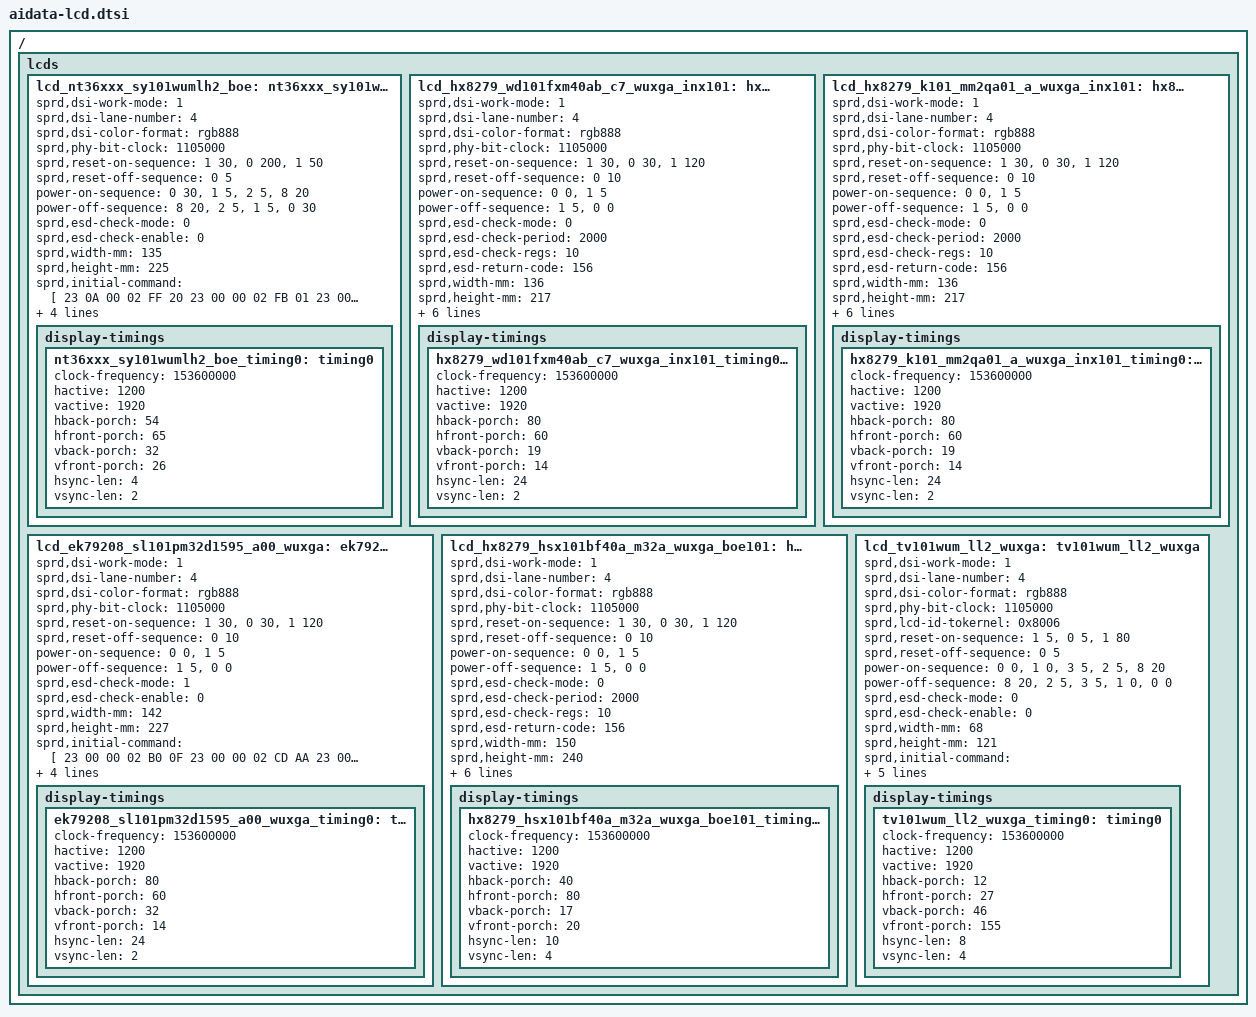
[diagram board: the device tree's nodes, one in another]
// SPDX-License-Identifier: GPL-2.0
/*
 * Aidata Adt1061 LCD Panel
 */

/ { lcds {
	lcd_nt36xxx_sy101wumlh2_boe: nt36xxx_sy101wumlh2_boe {
		sprd,dsi-work-mode = <1>; /* video burst mode */
		sprd,dsi-lane-number = <4>;
		sprd,dsi-color-format = "rgb888";

		sprd,phy-bit-clock = <1105000>;	/* kbps */

		sprd,reset-on-sequence = <1 30>, <0 200>, <1 50>;
		sprd,reset-off-sequence = <0 5>;

		power-on-sequence = <0 30>, <1 5>, <2 5>, <8 20>;
		power-off-sequence = <8 20>, <2 5>, <1 5>, <0 30>;

		sprd,esd-check-mode = <0>;
		sprd,esd-check-enable = <0>;

		sprd,width-mm = <135>;
		sprd,height-mm = <225>;

		sprd,initial-command = [
			23  0A  00  02  FF  20
			23  00  00  02  FB  01
			23  00  00  02  05  D1
			23  00  00  02  07  8C
			23  00  00  02  08  46
			23  00  00  02  0D  63
			23  00  00  02  0E  AC
			23  00  00  02  0F  5F
			23  00  00  02  89  79
			23  00  00  02  8A  79
			23  00  00  02  8B  79
			23  00  00  02  8C  79
			23  00  00  02  95  FF
			23  00  00  02  96  FF
			23  00  00  02  30  11
			23  00  00  02  58  60
			23  00  00  02  6D  66
			23  00  00  02  75  A2
			23  00  00  02  77  B3
			39  00  00  11  B0  00  B6  00  BF  00  D3  00  E4  00  F2  01  01  01  0D  01  1A
			39  00  00  11  B1  01  27  01  4F  01  71  01  A6  01  D3  02  19  02  52  02  54
			39  00  00  11  B2  02  8D  02  CF  02  F7  03  2C  03  4D  03  79  03  86  03  95
			39  00  00  0D  B3  03  A4  03  B4  03  D5  03  ED  03  FE  03  FF
			39  00  00  11  B4  00  16  00  30  00  57  00  77  00  93  00  AB  00  C1  00  D4
			39  00  00  11  B5  00  E5  01  1F  01  4B  01  8E  01  C0  02  0D  02  4B  02  4D
			39  00  00  11  B6  02  88  02  CB  02  F2  03  27  03  4A  03  74  03  83  03  91
			39  00  00  0D  B7  03  A1  03  B2  03  D2  03  EC  03  FE  03  FF
			39  00  00  11  B8  00  08  00  2C  00  57  00  7A  00  99  00  B1  00  C7  00  DC
			39  00  00  11  B9  00  EE  01  28  01  54  01  96  01  C7  02  13  02  4F  02  51
			39  00  00  11  BA  02  8B  02  CD  02  F4  03  2A  03  4D  03  78  03  86  03  94
			39  00  00  0D  BB  03  A4  03  B4  03  D5  03  EC  03  FE  03  FF
			23  00  00  02  FF  21
			23  00  00  02  FB  01
			39  00  00  11  B0  00  AE  00  B7  00  CB  00  DC  00  EA  00  F9  01  05  01  12
			39  00  00  11  B1  01  1F  01  47  01  69  01  9E  01  CB  02  11  02  4A  02  4C
			39  00  00  11  B2  02  85  02  C7  02  EF  03  24  03  45  03  71  03  7E  03  8D
			39  00  00  0D  B3  03  9C  03  AC  03  CD  03  E5  03  F6  03  F7
			39  00  00  11  B4  00  0E  00  28  00  4F  00  6F  00  8B  00  A3  00  B9  00  CC
			39  00  00  11  B5  00  DD  01  17  01  43  01  86  01  B8  02  05  02  43  02  45
			39  00  00  11  B6  02  80  02  C3  02  EA  03  1F  03  42  03  6C  03  7B  03  89
			39  00  00  0D  B7  03  99  03  AA  03  CA  03  E4  03  F6  03  F7
			39  00  00  11  B8  00  00  00  24  00  4F  00  72  00  91  00  A9  00  BF  00  D4
			39  00  00  11  B9  00  E6  01  20  01  4C  01  8E  01  BF  02  0B  02  47  02  49
			39  00  00  11  BA  02  83  02  C5  02  EC  03  22  03  45  03  70  03  7E  03  8C
			39  00  00  0D  BB  03  9C  03  AC  03  CD  03  E4  03  F6  03  F7
			23  00  00  02  FF  24
			23  00  00  02  FB  01
			23  00  00  02  00  00
			23  00  00  02  01  00
			23  00  00  02  02  22
			23  00  00  02  03  08
			23  00  00  02  04  04
			23  00  00  02  05  23
			23  00  00  02  06  21
			23  00  00  02  07  20
			23  00  00  02  08  0F
			23  00  00  02  09  0F
			23  00  00  02  0A  0E
			23  00  00  02  0B  0E
			23  00  00  02  0C  0D
			23  00  00  02  0D  0D
			23  00  00  02  0E  0C
			23  00  00  02  0F  0C
			23  00  00  02  10  00
			23  00  00  02  11  00
			23  00  00  02  12  00
			23  00  00  02  13  00
			23  00  00  02  14  00
			23  00  00  02  15  00
			23  00  00  02  16  00
			23  00  00  02  17  00
			23  00  00  02  18  22
			23  00  00  02  19  08
			23  00  00  02  1A  04
			23  00  00  02  1B  23
			23  00  00  02  1C  21
			23  00  00  02  1D  20
			23  00  00  02  1E  0F
			23  00  00  02  1F  0F
			23  00  00  02  20  0E
			23  00  00  02  21  0E
			23  00  00  02  22  0D
			23  00  00  02  23  0D
			23  00  00  02  24  0C
			23  00  00  02  25  0C
			23  00  00  02  26  00
			23  00  00  02  27  00
			23  00  00  02  28  00
			23  00  00  02  29  00
			23  00  00  02  2A  00
			23  00  00  02  2B  00
			23  00  00  02  2F  54
			23  00  00  02  33  54
			23  00  00  02  3A  9A
			23  00  00  02  3B  A0
			23  00  00  02  3D  91
			23  00  00  02  3F  08
			23  00  00  02  43  08
			23  00  00  02  4A  9A
			23  00  00  02  4B  A0
			23  00  00  02  4C  91
			23  00  00  02  4D  43
			23  00  00  02  4E  21
			23  00  00  02  51  12
			23  00  00  02  52  34
			39  00  00  03  55  86  07
			23  00  00  02  56  04
			23  00  00  02  58  21
			23  00  00  02  59  30
			23  00  00  02  5A  BA
			23  00  00  02  5B  96
			39  00  00  03  5E  00  12
			23  00  00  02  5F  00
			23  00  00  02  65  82
			23  00  00  02  AD  00
			23  00  00  02  AE  01
			23  00  00  02  AF  0C
			23  00  00  02  B0  16
			23  00  00  02  B1  0B
			23  00  00  02  B2  15
			23  00  00  02  B3  00
			23  00  00  02  C4  20
			39  00  00  0D  B6  05  00  05  00  00  00  00  00  05  05  00  00
			23  00  00  02  60  96
			23  00  00  02  61  80
			23  00  00  02  63  70
			23  00  00  02  92  DF
			23  00  00  02  93  1A
			23  00  00  02  94  0A
			23  00  00  02  D7  55
			23  00  00  02  DA  0A
			23  00  00  02  DE  08
			23  00  00  02  DB  05
			23  00  00  02  DC  DF
			23  00  00  02  DD  22
			23  00  00  02  DF  05
			23  00  00  02  E0  DF
			23  00  00  02  E1  05
			23  00  00  02  E2  DF
			23  00  00  02  E3  05
			23  00  00  02  E4  DF
			23  00  00  02  E5  05
			23  00  00  02  E6  DF
			23  00  00  02  5C  88
			23  00  00  02  5D  08
			23  00  00  02  8D  88
			23  00  00  02  8E  08
			23  00  00  02  B5  90
			23  00  00  02  FF  25
			23  00  00  02  FB  01
			23  00  00  02  05  04
			23  00  00  02  19  07
			23  00  00  02  1F  BA
			23  00  00  02  20  96
			23  00  00  02  26  BA
			23  00  00  02  27  96
			23  00  00  02  33  BA
			23  00  00  02  34  96
			23  00  00  02  3F  E0
			23  00  00  02  40  00
			23  00  00  02  44  00
			23  00  00  02  45  40
			23  00  00  02  48  BA
			23  00  00  02  49  96
			23  00  00  02  5B  00
			23  00  00  02  5C  00
			23  00  00  02  5D  00
			23  00  00  02  5E  D0
			23  00  00  02  61  BA
			23  00  00  02  62  96
			23  00  00  02  F1  10
			23  00  00  02  FF  2A
			23  00  00  02  FB  01
			23  00  00  02  64  16
			23  00  00  02  67  16
			23  00  00  02  6A  16
			23  00  00  02  73  9E
			23  00  00  02  76  16
			23  00  00  02  79  9E
			23  00  00  02  7C  16
			23  00  00  02  A2  F3
			23  00  00  02  A3  FF
			23  00  00  02  A4  FF
			23  00  00  02  A5  FF
			23  00  00  02  D6  08
			23  00  00  02  FF  26
			23  00  00  02  FB  01
			23  00  00  02  00  A1
			23  00  00  02  0A  F2
			23  00  00  02  04  28
			23  00  00  02  06  2A
			23  00  00  02  0C  11
			23  00  00  02  0D  00
			23  00  00  02  0F  09
			23  00  00  02  11  10
			23  00  00  02  12  50
			23  00  00  02  13  6A
			23  00  00  02  14  76
			23  00  00  02  15  00
			23  00  00  02  16  90
			23  00  00  02  17  A0
			23  00  00  02  18  86
			23  00  00  02  19  0F
			23  00  00  02  1A  9C
			23  00  00  02  1B  0E
			23  00  00  02  1C  DC
			23  00  00  02  22  00
			23  00  00  02  23  00
			23  00  00  02  2A  0F
			23  00  00  02  2B  9C
			23  00  00  02  1D  00
			23  00  00  02  1E  DF
			23  00  00  02  1F  DF
			23  00  00  02  24  00
			23  00  00  02  25  DF
			23  00  00  02  2F  05
			23  00  00  02  30  DF
			23  00  00  02  31  00
			23  00  00  02  32  DF
			23  00  00  02  39  00
			23  00  00  02  3A  DF
			23  00  00  02  20  01
			23  00  00  02  33  11
			23  00  00  02  34  78
			23  00  00  02  35  16
			23  00  00  02  C8  00
			23  00  00  02  C9  00
			23  00  00  02  CA  4E
			23  00  00  02  CB  00
			23  00  00  02  A9  6D
			23  00  00  02  AA  71
			23  00  00  02  AB  73
			23  00  00  02  AC  76
			23  00  00  02  FF  27
			23  00  00  02  FB  01
			23  00  00  02  58  00
			23  00  00  02  00  00
			23  00  00  02  78  00
			23  00  00  02  C3  00
			23  00  00  02  D1  24
			23  00  00  02  D2  30
			23  00  00  02  FF  23
			23  00  00  02  FB  01
			23  00  00  02  00  80
			23  00  00  02  05  2A
			23  00  00  02  07  00
			23  00  00  02  11  01
			23  00  00  02  12  68
			23  00  00  02  15  E9
			23  00  00  02  16  0C
			23  00  00  02  2B  10
			23  00  00  02  58  FF
			23  00  00  02  59  FF
			23  00  00  02  5A  FE
			23  00  00  02  5B  FD
			23  00  00  02  5C  FD
			23  00  00  02  5D  FC
			23  00  00  02  5E  FB
			23  00  00  02  5F  F9
			23  00  00  02  60  F7
			23  00  00  02  61  F3
			23  00  00  02  62  EA
			23  00  00  02  63  E6
			23  00  00  02  64  E0
			23  00  00  02  65  DD
			23  00  00  02  66  DB
			23  00  00  02  67  D9
			23  00  00  02  19  00
			23  00  00  02  1A  00
			23  00  00  02  1B  08
			23  00  00  02  1C  0A
			23  00  00  02  1D  0C
			23  00  00  02  1E  12
			23  00  00  02  1F  16
			23  00  00  02  20  1A
			23  00  00  02  21  1C
			23  00  00  02  22  20
			23  00  00  02  23  24
			23  00  00  02  24  28
			23  00  00  02  25  2C
			23  00  00  02  26  30
			23  00  00  02  27  38
			23  00  00  02  28  3C
			23  00  00  02  FF  E0
			23  00  00  02  FB  01
			23  00  00  02  14  60
			23  00  00  02  16  C0
			23  00  00  02  FF  F0
			23  00  00  02  FB  01
			23  00  00  02  3A  08
			23  00  00  02  FF  10
			23  00  00  02  FB  01
			23  00  00  02  B9  01
			23  00  00  02  FF  20
			23  00  00  02  FB  01
			23  00  00  02  18  40
			23  00  00  02  FF  10
			23  00  00  02  FB  01
			23  00  00  02  B9  02
			23  00  00  02  35  00
			39  00  00  03  51  0F  FF
			23  00  00  02  53  2C
			23  00  00  02  55  00
			23  00  00  02  BB  13
			39  00  00  06  3B  03  0A  1A  04  04
			23  00  00  02  FF  25
			23  00  00  02  EC  00
			23  00  00  02  FF  10
			23  00  00  02  FB  01
			13  78  00  01  11
			13  32  00  01  29
		];

		sprd,sleep-in-command = [
			13  0A  00  01  28
			13  78  00  01  10
		];

		sprd,sleep-out-command = [
			13  78  00  01  11
			13  32  00  01  29
		];

		display-timings {
			nt36xxx_sy101wumlh2_boe_timing0: timing0 {
				clock-frequency = <153600000>;
				hactive = <1200>;
				vactive = <1920>;
				hback-porch = <54>;
				hfront-porch = <65>;
				vback-porch = <32>;
				vfront-porch = <26>;
				hsync-len = <4>;
				vsync-len = <2>;
			};
		};
	};

	lcd_hx8279_wd101fxm40ab_c7_wuxga_inx101: hx8279_wd101fxm40ab_c7_wuxga_inx101 {
		sprd,dsi-work-mode = <1>; /* video burst mode */
		sprd,dsi-lane-number = <4>;
		sprd,dsi-color-format = "rgb888";

		sprd,phy-bit-clock = <1105000>;	/* kbps */

		sprd,reset-on-sequence = <1 30>, <0 30>, <1 120>;
		sprd,reset-off-sequence = <0 10>;

		power-on-sequence = <0 0>, <1 5>;
		power-off-sequence = <1 5>, <0 0>;

		sprd,esd-check-mode = <0>;
		sprd,esd-check-period = <2000>;
		sprd,esd-check-regs = <10>;
		sprd,esd-return-code = <156>;

		sprd,width-mm = <136>;
		sprd,height-mm = <217>;

		sprd,initial-command = [
			23  00  00  02  B0  00
			23  00  00  02  C2  0C
			23  00  00  02  C4  0C
			23  00  00  02  BD  30
			23  00  00  02  B0  02
			23  00  00  02  C0  00
			23  00  00  02  C1  0A
			23  00  00  02  C2  13
			23  00  00  02  C3  20
			23  00  00  02  C4  1F
			23  00  00  02  C5  1E
			23  00  00  02  C6  1D
			23  00  00  02  C7  1C
			23  00  00  02  C8  19
			23  00  00  02  C9  17
			23  00  00  02  CA  17
			23  00  00  02  CB  18
			23  00  00  02  CC  1A
			23  00  00  02  CD  1E
			23  00  00  02  CE  20
			23  00  00  02  CF  23
			23  00  00  02  D0  07
			23  00  00  02  D1  00
			23  00  00  02  D2  00
			23  00  00  02  D3  0A
			23  00  00  02  D4  13
			23  00  00  02  D5  20
			23  00  00  02  D6  1F
			23  00  00  02  D7  1E
			23  00  00  02  D8  1D
			23  00  00  02  D9  1C
			23  00  00  02  DA  19
			23  00  00  02  DB  17
			23  00  00  02  DC  17
			23  00  00  02  DD  18
			23  00  00  02  DE  1A
			23  00  00  02  DF  1E
			23  00  00  02  E0  20
			23  00  00  02  E1  23
			23  00  00  02  E2  07
			23  00  00  02  B0  01
			23  00  00  02  D3  01
			23  00  00  02  E7  02
			23  00  00  02  D2  05
			23  00  00  02  E6  06
			23  00  00  02  D1  07
			23  00  00  02  E5  08
			23  00  00  02  D0  09
			23  00  00  02  E4  0A
			23  00  00  02  CF  0B
			23  00  00  02  E3  0C
			23  00  00  02  CE  1B
			23  00  00  02  E2  1C
			23  00  00  02  CD  1D
			23  00  00  02  E1  1E
			23  00  00  02  CA  11
			23  00  00  02  C9  12
			23  00  00  02  DE  11
			23  00  00  02  DD  12
			23  00  00  02  C8  0D
			23  00  00  02  DC  0E
			23  00  00  02  C3  0F
			23  00  00  02  D7  10
			23  00  00  02  C6  00
			23  00  00  02  C7  00
			23  00  00  02  C4  00
			23  00  00  02  C5  00
			23  00  00  02  D8  00
			23  00  00  02  D9  00
			23  00  00  02  DA  00
			23  00  00  02  DB  00
			23  00  00  02  B0  03
			23  00  00  02  BE  03
			23  00  00  02  CC  44
			23  00  00  02  C8  07
			23  00  00  02  C9  05
			23  00  00  02  CA  42
			23  00  00  02  E4  F0
			23  00  00  02  E5  0A
			23  00  00  02  DB  01
			23  00  00  02  D9  01
			23  00  00  02  D4  01
			23  00  00  02  D5  00
			23  00  00  02  D6  03
			23  00  00  02  D7  04
			23  00  00  02  D2  04
			23  00  00  02  D3  04
			23  00  00  02  CF  60
			23  00  00  02  CD  3E
			23  00  00  02  B0  00
			23  00  00  02  B2  40
			13  78  00  01  11
			13  14  00  01  29
		];

		sprd,sleep-in-command = [
			13  14  00  01  28
			13  64  00  01  10
		];

		sprd,sleep-out-command = [
			13  78  00  01  11
			13  14  00  01  29
		];

		display-timings {
			hx8279_wd101fxm40ab_c7_wuxga_inx101_timing0: timing0 {
				clock-frequency = <153600000>;
				hactive = <1200>;
				vactive = <1920>;
				hback-porch = <80>;
				hfront-porch = <60>;
				vback-porch = <19>;
				vfront-porch = <14>;
				hsync-len = <24>;
				vsync-len = <2>;
			};
		};
	};

	lcd_hx8279_k101_mm2qa01_a_wuxga_inx101: hx8279_k101_mm2qa01_a_wuxga_inx101 {
		sprd,dsi-work-mode = <1>; /* video burst mode */
		sprd,dsi-lane-number = <4>;
		sprd,dsi-color-format = "rgb888";

		sprd,phy-bit-clock = <1105000>;	/* kbps */

		sprd,reset-on-sequence = <1 30>, <0 30>, <1 120>;
		sprd,reset-off-sequence = <0 10>;

		power-on-sequence = <0 0>, <1 5>;
		power-off-sequence = <1 5>, <0 0>;

		sprd,esd-check-mode = <0>;
		sprd,esd-check-period = <2000>;
		sprd,esd-check-regs = <10>;
		sprd,esd-return-code = <156>;

		sprd,width-mm = <136>;
		sprd,height-mm = <217>;

		sprd,initial-command = [
			23  00  00  02  B0  01
			23  00  00  02  C3  0F
			23  00  00  02  C4  00
			23  00  00  02  C5  00
			23  00  00  02  C6  00
			23  00  00  02  C7  00
			23  00  00  02  C8  0D
			23  00  00  02  C9  12
			23  00  00  02  CA  11
			23  00  00  02  CD  1D
			23  00  00  02  CE  1B
			23  00  00  02  CF  0B
			23  00  00  02  D0  09
			23  00  00  02  D1  07
			23  00  00  02  D2  05
			23  00  00  02  D3  01
			23  00  00  02  D7  10
			23  00  00  02  D8  00
			23  00  00  02  D9  00
			23  00  00  02  DA  00
			23  00  00  02  DB  00
			23  00  00  02  DC  0E
			23  00  00  02  DD  12
			23  00  00  02  DE  11
			23  00  00  02  E1  1E
			23  00  00  02  E2  1C
			23  00  00  02  E3  0C
			23  00  00  02  E4  0A
			23  00  00  02  E5  08
			23  00  00  02  E6  06
			23  00  00  02  E7  02
			23  00  00  02  B0  03
			23  00  00  02  BE  03
			23  00  00  02  CC  44
			23  00  00  02  C8  07
			23  00  00  02  C9  05
			23  00  00  02  CA  42
			23  00  00  02  CD  3E
			23  00  00  02  CF  60
			23  00  00  02  D2  04
			23  00  00  02  D3  04
			23  00  00  02  D4  01
			23  00  00  02  D5  00
			23  00  00  02  D6  03
			23  00  00  02  D7  04
			23  00  00  02  D9  01
			23  00  00  02  DB  01
			23  00  00  02  E4  F0
			23  00  00  02  E5  0A
			23  00  00  02  B0  00
			23  00  00  02  BD  63
			23  00  00  02  C2  08
			23  00  00  02  C4  10
			23  00  00  02  B0  02
			23  00  00  02  C0  00
			23  00  00  02  C1  0A
			23  00  00  02  C2  20
			23  00  00  02  C3  24
			23  00  00  02  C4  23
			23  00  00  02  C5  29
			23  00  00  02  C6  23
			23  00  00  02  C7  1C
			23  00  00  02  C8  19
			23  00  00  02  C9  17
			23  00  00  02  CA  17
			23  00  00  02  CB  18
			23  00  00  02  CC  1A
			23  00  00  02  CD  1E
			23  00  00  02  CE  20
			23  00  00  02  CF  23
			23  00  00  02  D0  07
			23  00  00  02  D1  00
			23  00  00  02  D2  00
			23  00  00  02  D3  0A
			23  00  00  02  D4  13
			23  00  00  02  D5  1C
			23  00  00  02  D6  1A
			23  00  00  02  D7  13
			23  00  00  02  D8  17
			23  00  00  02  D9  1C
			23  00  00  02  DA  19
			23  00  00  02  DB  17
			23  00  00  02  DC  17
			23  00  00  02  DD  18
			23  00  00  02  DE  1A
			23  00  00  02  DF  1E
			23  00  00  02  E0  20
			23  00  00  02  E1  23
			23  00  00  02  E2  07
			13  78  00  01  11
			13  14  00  01  29
		];

		sprd,sleep-in-command = [
			13  14  00  01  28
			13  64  00  01  10
		];

		sprd,sleep-out-command = [
			13  78  00  01  11
			13  14  00  01  29
		];

		display-timings {
			hx8279_k101_mm2qa01_a_wuxga_inx101_timing0: timing0 {
				clock-frequency = <153600000>;
				hactive = <1200>;
				vactive = <1920>;
				hback-porch = <80>;
				hfront-porch = <60>;
				vback-porch = <19>;
				vfront-porch = <14>;
				hsync-len = <24>;
				vsync-len = <2>;
			};
		};
	};

	lcd_ek79208_sl101pm32d1595_a00_wuxga: ek79208_sl101pm32d1595_a00_wuxga {
		sprd,dsi-work-mode = <1>; /* video burst mode */
		sprd,dsi-lane-number = <4>;
		sprd,dsi-color-format = "rgb888";

		sprd,phy-bit-clock = <1105000>;	/* kbps */

		sprd,reset-on-sequence = <1 30>, <0 30>, <1 120>;
		sprd,reset-off-sequence = <0 10>;

		power-on-sequence = <0 0>, <1 5>;
		power-off-sequence = <1 5>, <0 0>;

		sprd,esd-check-mode = <1>;
		sprd,esd-check-enable = <0>;

		sprd,width-mm = <142>;
		sprd,height-mm = <227>;

		sprd,initial-command = [
			23  00  00  02  B0  0F
			23  00  00  02  CD  AA
			23  00  00  02  30  00
			23  00  00  02  32  00
			23  00  00  02  3A  8F
			23  00  00  02  3D  12
			23  00  00  02  3F  1F
			23  00  00  02  40  0F
			23  00  00  02  30  01
			23  00  00  02  00  01
			23  00  00  02  31  66
			23  00  00  02  32  10
			23  00  00  02  33  74
			23  00  00  02  35  00
			23  00  00  02  36  01
			39  00  00  0D  3A  00  00  10  10  00  00  10  10  00  00  10  10
			39  00  00  0C  3B  22  19  1D  23  23  21  20  17  15  13  11
			39  00  00  0B  3C  0F  0D  0B  09  05  01  23  23  23  00
			39  00  00  0C  3D  22  18  1C  23  23  21  20  16  14  12  10
			39  00  00  0B  3E  0E  0C  0A  08  04  00  23  23  23  00
			23  00  00  02  3F  01
			23  00  00  02  40  B8
			23  00  00  02  41  01
			23  00  00  02  46  87
			23  00  00  02  30  02
			39  00  00  0B  3A  3E  32  2E  2C  35  34  33  35  3A  3D
			39  00  00  08  3B  3B  39  37  2B  1E  0F  00
			39  00  00  0B  3C  3E  32  2E  2C  35  34  33  35  3A  3D
			39  00  00  08  3D  3B  39  37  2B  1E  0F  00
			39  00  00  0B  3E  00  00  00  00  00  00  00  00  00  00
			23  00  00  02  30  05
			23  00  00  02  31  19
			23  00  00  02  30  07
			23  00  00  02  35  B8
			23  00  00  02  30  08
			23  00  00  02  5C  20
			23  00  00  02  5D  04
			23  00  00  02  30  0A
			23  00  00  02  39  05
			23  00  00  02  3A  1D
			23  00  00  02  4C  04
			23  00  00  02  30  08
			23  00  00  02  33  12
			23  00  00  02  30  01
			23  00  00  02  37  66
			23  00  00  02  30  0F
			13  78  00  01  11
			13  14  00  01  29
		];

		sprd,sleep-in-command = [
			13  0A  00  01  28
			13  78  00  01  10
		];

		sprd,sleep-out-command = [
			13  78  00  01  11
			13  14  00  01  29
		];

		display-timings {
			ek79208_sl101pm32d1595_a00_wuxga_timing0: timing0 {
				clock-frequency = <153600000>;
				hactive = <1200>;
				vactive = <1920>;
				hback-porch = <80>;
				hfront-porch = <60>;
				vback-porch = <32>;
				vfront-porch = <14>;
				hsync-len = <24>;
				vsync-len = <2>;
			};
		};
	};

	lcd_hx8279_hsx101bf40a_m32a_wuxga_boe101: hx8279_hsx101bf40a_m32a_wuxga_boe101 {
		sprd,dsi-work-mode = <1>; /* video burst mode */
		sprd,dsi-lane-number = <4>;
		sprd,dsi-color-format = "rgb888";

		sprd,phy-bit-clock = <1105000>;	/* kbps */

		sprd,reset-on-sequence = <1 30>, <0 30>, <1 120>;
		sprd,reset-off-sequence = <0 10>;

		power-on-sequence = <0 0>, <1 5>;
		power-off-sequence = <1 5>, <0 0>;

		sprd,esd-check-mode = <0>;
		sprd,esd-check-period = <2000>;
		sprd,esd-check-regs = <10>;
		sprd,esd-return-code = <156>;

		sprd,width-mm = <150>;
		sprd,height-mm = <240>;

		sprd,initial-command = [
			13  78  00  01  11
			13  14  00  01  29
		];

		sprd,sleep-in-command = [
			13  14  00  01  28
			13  64  00  01  10
		];

		sprd,sleep-out-command = [
			13  78  00  01  11
			13  14  00  01  29
		];

		display-timings {
			hx8279_hsx101bf40a_m32a_wuxga_boe101_timing0: timing0 {
				clock-frequency = <153600000>;
				hactive = <1200>;
				vactive = <1920>;
				hback-porch = <40>;
				hfront-porch = <80>;
				vback-porch = <17>;
				vfront-porch = <20>;
				hsync-len = <10>;
				vsync-len = <4>;
			};
		};
	};

	lcd_tv101wum_ll2_wuxga: tv101wum_ll2_wuxga {
		sprd,dsi-work-mode = <1>; /* video burst mode */
		sprd,dsi-lane-number = <4>;
		sprd,dsi-color-format = "rgb888";

		sprd,phy-bit-clock = <1105000>;	/* kbps */

		sprd,lcd-id-tokernel = <0x8006>;
		sprd,reset-on-sequence = <1 5>, <0 5>, <1 80>;
		sprd,reset-off-sequence = <0 5>;

		power-on-sequence = <0 0>, <1 0>, <3 5>, <2 5>, <8 20>;
		power-off-sequence = <8 20>, <2 5>, <3 5>, <1 0>, <0 0>;

		sprd,esd-check-mode = <0>;
		sprd,esd-check-enable = <0>;

		sprd,width-mm = <68>;
		sprd,height-mm = <121>;

		sprd,initial-command = [
			39  00  00  03  50  5A  0C
			23  05  00  02  80  FE
			13  96  00  01  11
			13  32  00  01  29
		];

		sprd,sleep-in-command = [
			13  01  00  01  00
			13  0A  00  01  28
			13  78  00  01  10
			23  0A  00  02  4F  01
		];

		sprd,sleep-out-command = [
			39  00  00  03  50  5A  0C
			23  05  00  02  80  FE
			13  78  00  01  11
			13  32  00  01  29
		];

		display-timings {
			tv101wum_ll2_wuxga_timing0: timing0 {
				clock-frequency = <153600000>;
				hactive = <1200>;
				vactive = <1920>;
				hback-porch = <12>;
				hfront-porch = <27>;
				vback-porch = <46>;
				vfront-porch = <155>;
				hsync-len = <8>;
				vsync-len = <4>;
			};
		};
	};
};};
